# APM32M35XX register map
File version: 1.0
Registers are 32-bit, read-write, reset 0x0 unless marked. A register's access mark holds for its fields unless they carry their own. Offsets are from the block's base; [hi:lo] are bit positions; {n}, {i} and the like mark numbered series.

## COMP — Comparator
Base 0x4001001C
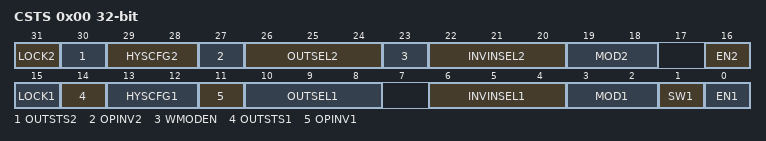
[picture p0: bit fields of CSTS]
0x00 CSTS access per field — control and status register
  [31] LOCK2 rw — Comparator 2 lock
  [30] OUTSTS2 ro — Comparator 2 output
  [29:28] HYSCFG2 rw — Comparator 2 hysteresis
  [27] OPINV2 rw — Comparator 2 output polarity
  [26:24] OUTSEL2 rw — Comparator 2 output selection
  [23] WMODEN rw — Window mode enable
  [22:20] INVINSEL2 rw — Comparator 2 inverting input selection
  [19:18] MOD2 rw — Comparator 2 mode
  [16] EN2 rw — Comparator 2 enable
  [15] LOCK1 rw — Comparator 1 lock
  [14] OUTSTS1 ro — Comparator 1 output
  [13:12] HYSCFG1 rw — Comparator 1 hysteresis
  [11] OPINV1 rw — Comparator 1 output polarity
  [10:8] OUTSEL1 rw — Comparator 1 output selection
  [6:4] INVINSEL1 rw — Comparator 1 inverting input selection
  [3:2] MOD1 rw — Comparator 1 mode
  [1] SW1 rw — COMP1SW
  [0] EN1 rw — Comparator 1 enable

## FMC — Flash
Base 0x40022000
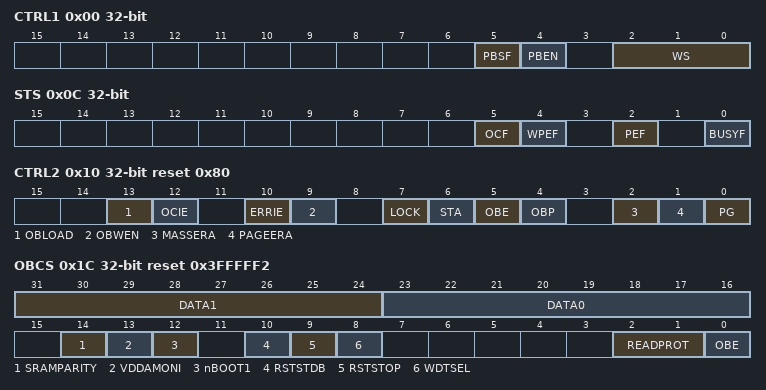
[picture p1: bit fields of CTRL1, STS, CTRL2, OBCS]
0x00 CTRL1 access per field — Flash access control register
  [5] PBSF ro
  [4] PBEN rw
  [2:0] WS rw — LATENCY
0x04 KEY wo — Flash key register
  [31:0] KEY — Flash Key
0x08 OBKEY wo — Flash option key register
  [31:0] OBKEY — Option byte key
0x0C STS access per field — Flash status register
  [5] OCF rw — End of operation
  [4] WPEF rw — Write protection error
  [2] PEF rw — Programming error
  [0] BUSYF ro — Busy
0x10 CTRL2 reset 0x80 — Flash control register
  [13] OBLOAD — Force option byte loading
  [12] OCIE — End of operation interrupt enable
  [10] ERRIE — Error interrupt enable
  [9] OBWEN — Option bytes write enable
  [7] LOCK
  [6] STA — Start
  [5] OBE — Option byte erase
  [4] OBP — Option byte programming
  [2] MASSERA — Mass erase
  [1] PAGEERA — Page erase
  [0] PG — Programming
0x14 ADDR wo — Flash address register
  [31:0] ADDR — Flash address
0x1C OBCS ro reset 0x3FFFFF2 — Option byte register
  [31:24] DATA1
  [23:16] DATA0
  [14] SRAMPARITY — RPC
  [13] VDDAMONI — VDDAMON
  [12] nBOOT1 — BOT1
  [10] RSTSTDB — RSTSTDBY
  [9] RSTSTOP
  [8] WDTSEL
  [2:1] READPROT — Level x protection status
  [0] OBE — Option byte error
0x20 WRTPROT ro reset 0xFFFFFFFF — Write protection register
  [31:0] WRTPROT — Write protect

## DBG — Debug support
Base 0x40015800
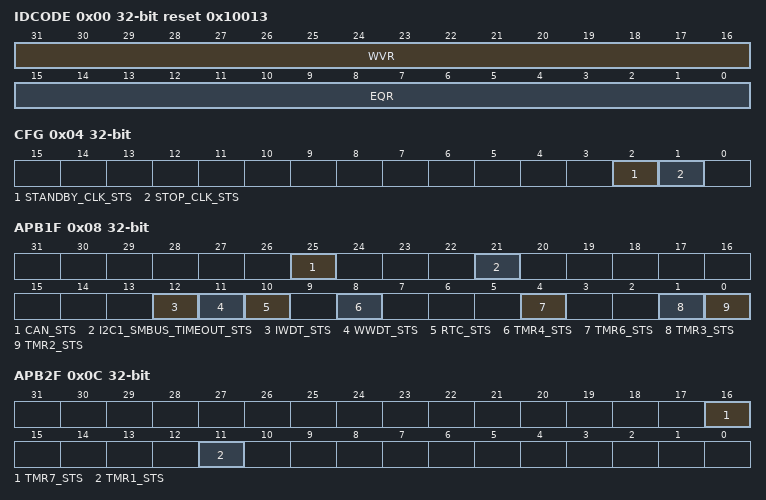
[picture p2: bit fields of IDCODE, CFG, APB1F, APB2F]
0x00 IDCODE ro reset 0x10013 — MCU Device ID Code Register
  [31:16] WVR — Revision Identifier
  [15:0] EQR — Device Identifier
0x04 CFG — Debug MCU Configuration Register
  [2] STANDBY_CLK_STS — Debug Standby Mode
  [1] STOP_CLK_STS — Debug Stop Mode
0x08 APB1F — APB Low Freeze Register
  [25] CAN_STS — Debug CAN stopped when Core is halted
  [21] I2C1_SMBUS_TIMEOUT_STS — I2C1 SMBUS timeout mode stopped when Core is halted
  [12] IWDT_STS — Debug Independent Wachdog stopped when Core is halted
  [11] WWDT_STS — Debug Window Wachdog stopped when Core is halted
  [10] RTC_STS — Debug RTC stopped when Core is halted
  [8] TMR4_STS — Debug Timer 4 stopped when Core is halted
  [4] TMR6_STS — Debug Timer 6 stopped when Core is halted
  [1] TMR3_STS — Debug Timer 3 stopped when Core is halted
  [0] TMR2_STS — Debug Timer 2 stopped when Core is halted
0x0C APB2F — APB High Freeze Register
  [16] TMR7_STS — Debug Timer 7 stopped when Core is halted
  [11] TMR1_STS — Debug Timer 1 stopped when Core is halted

## NVIC — Nested Vectored Interrupt Controller
Base 0xE000E100
0x00 ISER — Interrupt Set Enable Register
  [31:0] SETENA
0x80 ICER — Interrupt Clear Enable Register
  [31:0] CLRENA
0x100 ISPR — Interrupt Set-Pending Register
  [31:0] SETPEND
0x180 ICPR — Interrupt Clear-Pending Register
  [31:0] CLRPEND
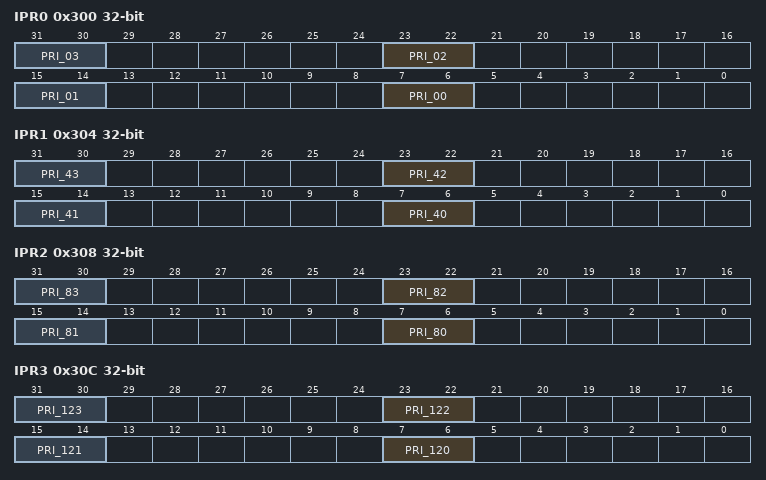
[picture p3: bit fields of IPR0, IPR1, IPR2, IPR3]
0x300 IPR0 — Interrupt Priority Register 0
  [8n+7:8n+6] PRI_{n:02} (n=0..3)
0x304 IPR1 — Interrupt Priority Register 1
  [8n-313:8n-314] PRI_{n} (n=40..43)
0x308 IPR2 — Interrupt Priority Register 2
  [8n-633:8n-634] PRI_{n} (n=80..83)
0x30C IPR3 — Interrupt Priority Register 3
  [8n-953:8n-954] PRI_{n} (n=120..123)
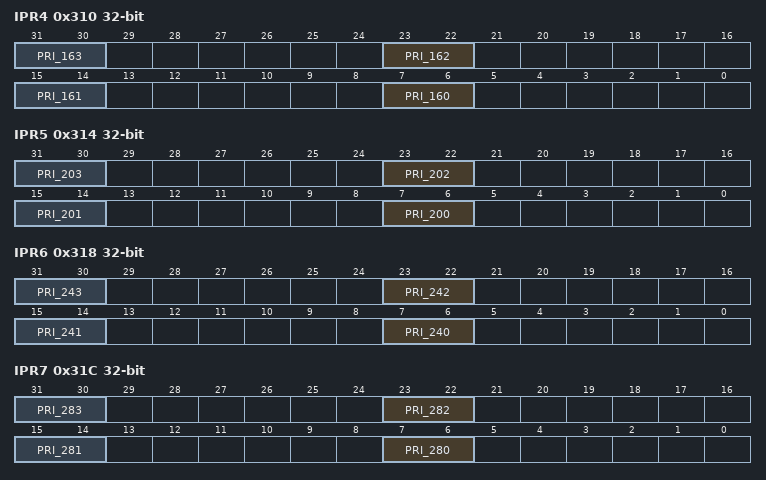
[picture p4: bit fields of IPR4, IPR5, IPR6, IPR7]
0x310 IPR4 — Interrupt Priority Register 4
  [8n-1273:8n-1274] PRI_{n} (n=160..163)
0x314 IPR5 — Interrupt Priority Register 5
  [8n-1593:8n-1594] PRI_{n} (n=200..203)
0x318 IPR6 — Interrupt Priority Register 6
  [8n-1913:8n-1914] PRI_{n} (n=240..243)
0x31C IPR7 — Interrupt Priority Register 7
  [8n-2233:8n-2234] PRI_{n} (n=280..283)

## PMU — Power control
Base 0x40007000
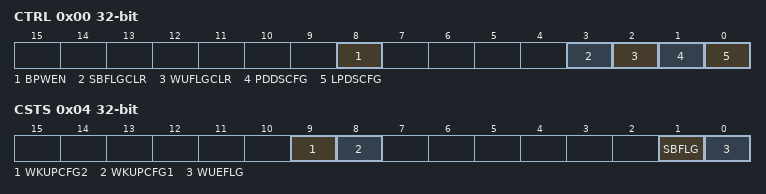
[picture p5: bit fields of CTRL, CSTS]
0x00 CTRL — power control register
  [8] BPWEN — Disable backup domain write protection
  [3] SBFLGCLR — Clear standby flag
  [2] WUFLGCLR — Clear wakeup flag
  [1] PDDSCFG — Power down deepsleep
  [0] LPDSCFG — Low-power deep sleep
0x04 CSTS access per field — power control/status register
  [9] WKUPCFG2 rw — Enable WKUP pin
  [8] WKUPCFG1 rw — Enable WKUP pin
  [1] SBFLG ro — Standby flag
  [0] WUEFLG ro — Wakeup flag

## TMR6 — Basic-timers
Base 0x40001000
Same registers: TMR7 0x40014000
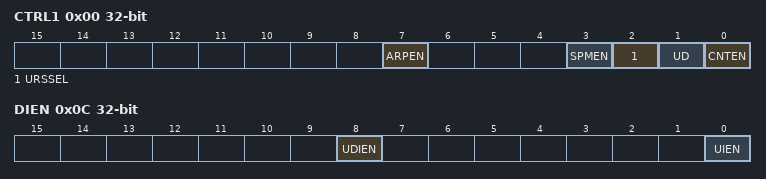
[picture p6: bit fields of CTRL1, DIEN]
0x00 CTRL1 — control register 1
  [7] ARPEN — Auto-reload preload enable
  [3] SPMEN — One-pulse mode
  [2] URSSEL — Update request source
  [1] UD — Update disable
  [0] CNTEN — Counter enable
0x04 CTRL2 — control register 2
  [6:4] MMSEL — Master mode selection
0x0C DIEN — DMA/Interrupt enable register
  [8] UDIEN — Update DMA request enable
  [0] UIEN — Update interrupt enable
0x10 STS — status register
  [0] UIFLG — Update interrupt flag
0x14 CEG wo — event generation register
  [0] UEG — Update generation
0x24 CNT — counter
  [15:0] CNT — Low counter value
0x28 PSC — prescaler
  [15:0] PSC — Prescaler value
0x2C AUTORLD reset 0xFFFF — auto-reload register
  [15:0] AUTORLD — Low Auto-reload value

## OPA — Operational amplifier
Base 0x40010034
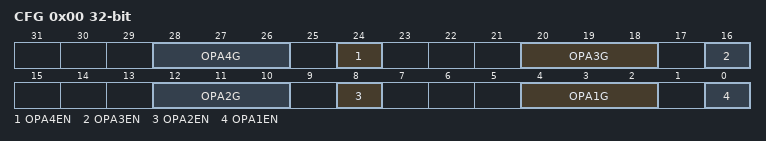
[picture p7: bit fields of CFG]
0x00 CFG — configuration register
  [8n-4:8n-6] OPA{n}G (n=1..4) — OPA{n} gain factor
  [24] OPA4EN — OPA4 enable
  [16] OPA3EN — OPA3 enable
  [8] OPA2EN — OPA2 Enable
  [0] OPA1EN — OPA1 enable

## M0CP — Coprocessor for the ARM cortex-M0+
Base 0x40024000
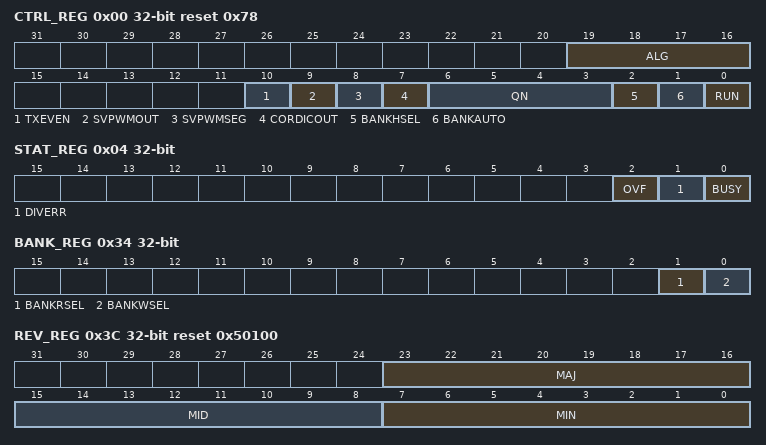
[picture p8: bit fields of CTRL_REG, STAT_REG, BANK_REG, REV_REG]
0x00 CTRL_REG access per field reset 0x78 — control register
  [19:16] ALG rw — Algebra
  [10] TXEVEN rw — TX interrupt enable
  [9] SVPWMOUT rw — SVPWM output
  [8] SVPWMSEG rw — SVPWM segmentation
  [7] CORDICOUT rw — CORDIC output
  [6:3] QN rw — Fixed point information setting
  [2] BANKHSEL rw — Bank select
  [1] BANKAUTO rw — Bank auto conversion
  [0] RUN wo
0x04 STAT_REG ro — status register
  [2] OVF — Overflow
  [1] DIVERR — Division
  [0] BUSY
0x08 TXIS_REG ro — TX interrupt status register
  [0] DONE — Done flag
0x0C TXIR_REG — TX region interrupt status register
  [0] DONE — Done flag
0x10 TXIE_REG — TX interrupt enable register
  [0] TXIEN — TX interrupt enable
0x14 X_REG — data for arameter and result of X
  [31:0] DATA
0x18 Y_REG — data for arameter and result of Y
  [31:0] DATA
0x1C Z_REG — data for arameter and result of Z
  [31:0] DATA
0x20 W_REG ro — data for result of W
  [31:0] DATA
0x34 BANK_REG — Bank operation register
  [1] BANKRSEL — Reading back select
  [0] BANKWSEL — Writting back select
0x3C REV_REG ro reset 0x50100 — Reversion register
  [23:16] MAJ — Major reversion
  [15:8] MID — Medium reversion
  [7:0] MIN — Mininum reversion
